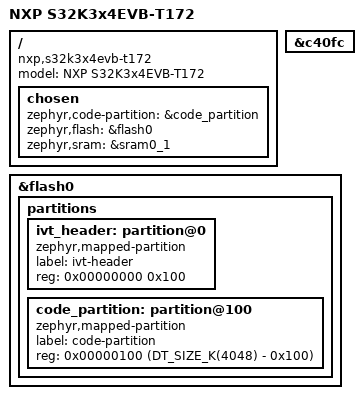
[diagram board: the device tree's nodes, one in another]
/*
 * SPDX-FileCopyrightText: Copyright The Zephyr Project Contributors
 *
 * SPDX-License-Identifier: Apache-2.0
 */
/dts-v1/;

#include <arm/nxp/s32/nxp_s32k344_m7.dtsi>
#include "s32k3x4evb_t172_s32k344.dtsi"

/ {
	model = "NXP S32K3x4EVB-T172";
	compatible = "nxp,s32k3x4evb-t172";

	chosen {
		zephyr,code-partition = &code_partition;
		zephyr,flash = &flash0;
		zephyr,sram = &sram0_1;
	};
};

&c40fc {
	status = "okay";
};

&flash0 {
	status = "okay";
	ranges = <0x0 0x0 DT_SIZE_K(4048)>;
	#address-cells = <1>;
	#size-cells = <1>;

	partitions {
		ranges;
		#address-cells = <1>;
		#size-cells = <1>;

		ivt_header: partition@0 {
			compatible = "zephyr,mapped-partition";
			label = "ivt-header";
			reg = <0x00000000 0x100>;
		};

		code_partition: partition@100 {
			compatible = "zephyr,mapped-partition";
			label = "code-partition";
			reg = <0x00000100 (DT_SIZE_K(4048) - 0x100)>;
		};
	};
};
